# ESP32-C6 register map
Vendor: ESPRESSIF SYSTEMS (SHANGHAI) CO., LTD.; Series: ESP32 C-Series; File version: 12
CPU: RV32IMAC r0p0, little endian, no MPU, no FPU, 0 interrupt priority bits
Address unit: 32 bits
Registers are 32-bit, read-write, reset 0x0 unless marked. A register's access mark holds for its fields unless they carry their own. Offsets are from the block's base; [hi:lo] are bit positions; {n}, {i} and the like mark numbered series.

## SPI1 — SPI (Serial Peripheral Interface) Controller 1
Base 0x60003000
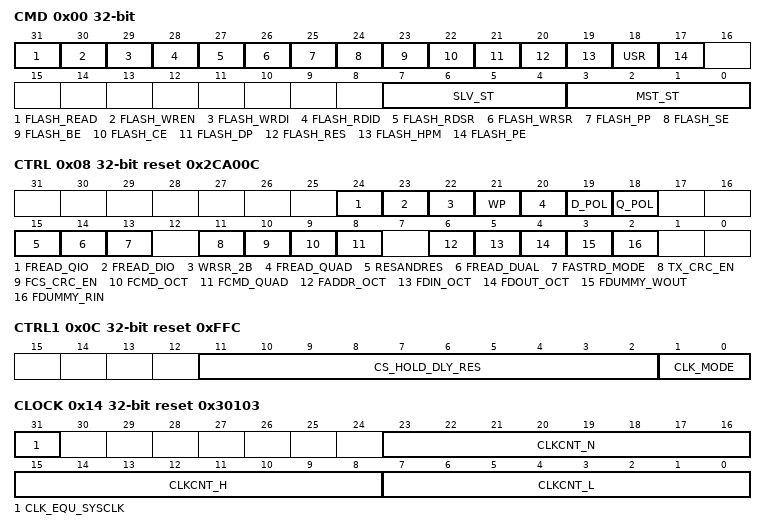
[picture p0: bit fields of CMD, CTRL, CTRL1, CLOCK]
0x00 CMD access per field — SPI1 memory command register
  [31] FLASH_READ rw — Read flash enable. Read flash operation will be triggered when the bit is set. The bit will be cleared once the operation done. 1: enable 0: disable.
  [30] FLASH_WREN rw — Write flash enable. Write enable command will be sent when the bit is set. The bit will be cleared once the operation done. 1: enable 0: disable.
  [29] FLASH_WRDI rw — Write flash disable. Write disable command will be sent when the bit is set. The bit will be cleared once the operation done. 1: enable 0: disable.
  [28] FLASH_RDID rw — Read JEDEC ID . Read ID command will be sent when the bit is set. The bit will be cleared once the operation done. 1: enable 0: disable.
  [27] FLASH_RDSR rw — Read status register-1. Read status operation will be triggered when the bit is set. The bit will be cleared once the operation done.1: enable 0: disable.
  [26] FLASH_WRSR rw — Write status register enable. Write status operation will be triggered when the bit is set. The bit will be cleared once the operation done.1: enable 0: disable.
  [25] FLASH_PP rw — Page program enable(1 byte ~256 bytes data to be programmed). Page program operation will be triggered when the bit is set. The bit will be cleared once the operation done .1: enable 0: disable.
  [24] FLASH_SE rw — Sector erase enable(4KB). Sector erase operation will be triggered when the bit is set. The bit will be cleared once the operation done.1: enable 0: disable.
  [23] FLASH_BE rw — Block erase enable(32KB) . Block erase operation will be triggered when the bit is set. The bit will be cleared once the operation done.1: enable 0: disable.
  [22] FLASH_CE rw — Chip erase enable. Chip erase operation will be triggered when the bit is set. The bit will be cleared once the operation done.1: enable 0: disable.
  [21] FLASH_DP rw — Drive Flash into power down. An operation will be triggered when the bit is set. The bit will be cleared once the operation done.1: enable 0: disable.
  [20] FLASH_RES rw — This bit combined with reg_resandres bit releases Flash from the power-down state or high performance mode and obtains the devices ID. The bit will be cleared once the operation done.1: enable 0: disable.
  [19] FLASH_HPM rw — Drive Flash into high performance mode. The bit will be cleared once the operation done.1: enable 0: disable.
  [18] USR rw — User define command enable. An operation will be triggered when the bit is set. The bit will be cleared once the operation done.1: enable 0: disable.
  [17] FLASH_PE rw — In user mode, it is set to indicate that program/erase operation will be triggered. The bit is combined with spi_mem_usr bit. The bit will be cleared once the operation done.1: enable 0: disable.
  [7:4] SLV_ST ro — The current status of SPI1 slave FSM: mspi_st. 0: idle state, 1: preparation state, 2: send command state, 3: send address state, 4: wait state, 5: read data state, 6:write data state, 7: done state, 8: read data end state.
  [3:0] MST_ST ro — The current status of SPI1 master FSM.
0x04 ADDR — SPI1 address register
  [31:0] USR_ADDR_VALUE — In user mode, it is the memory address. other then the bit0-bit23 is the memory address, the bit24-bit31 are the byte length of a transfer.
0x08 CTRL access per field reset 0x2CA00C — SPI1 control register.
  [24] FREAD_QIO rw — In the read operations address phase and read-data phase apply 4 signals. 1: enable 0: disable.
  [23] FREAD_DIO rw — In the read operations address phase and read-data phase apply 2 signals. 1: enable 0: disable.
  [22] WRSR_2B rw — two bytes data will be written to status register when it is set. 1: enable 0: disable.
  [21] WP rw — Write protect signal output when SPI is idle. 1: output high, 0: output low.
  [20] FREAD_QUAD rw — In the read operations read-data phase apply 4 signals. 1: enable 0: disable.
  [19] D_POL rw — The bit is used to set MOSI line polarity, 1: high 0, low
  [18] Q_POL rw — The bit is used to set MISO line polarity, 1: high 0, low
  [15] RESANDRES rw — The Device ID is read out to SPI_MEM_RD_STATUS register, this bit combine with spi_mem_flash_res bit. 1: enable 0: disable.
  [14] FREAD_DUAL rw — In the read operations, read-data phase apply 2 signals. 1: enable 0: disable.
  [13] FASTRD_MODE rw — This bit enable the bits: spi_mem_fread_qio, spi_mem_fread_dio, spi_mem_fread_qout and spi_mem_fread_dout. 1: enable 0: disable.
  [11] TX_CRC_EN ro — For SPI1, enable crc32 when writing encrypted data to flash. 1: enable 0:disable
  [10] FCS_CRC_EN ro — For SPI1, initialize crc32 module before writing encrypted data to flash. Active low.
  [9] FCMD_OCT ro — Apply 8 signals during command phase 1:enable 0: disable
  [8] FCMD_QUAD rw — Apply 4 signals during command phase 1:enable 0: disable
  [6] FADDR_OCT ro — Apply 8 signals during address phase 1:enable 0: disable
  [5] FDIN_OCT ro — Apply 8 signals during read-data phase 1:enable 0: disable
  [4] FDOUT_OCT ro — Apply 8 signals during write-data phase 1:enable 0: disable
  [3] FDUMMY_WOUT rw — In the dummy phase of a MSPI write data transfer when accesses to flash, the signal level of SPI bus is output by the MSPI controller.
  [2] FDUMMY_RIN rw — In the dummy phase of a MSPI read data transfer when accesses to flash, the signal level of SPI bus is output by the MSPI controller.
0x0C CTRL1 reset 0xFFC — SPI1 control1 register.
  [11:2] CS_HOLD_DLY_RES — After RES/DP/HPM command is sent, SPI1 waits (SPI_MEM_CS_HOLD_DELAY_RES[9:0] * 512) SPI_CLK cycles.
  [1:0] CLK_MODE — SPI clock mode bits. 0: SPI clock is off when CS inactive 1: SPI clock is delayed one cycle after CS inactive 2: SPI clock is delayed two cycles after CS inactive 3: SPI clock is alwasy on.
0x10 CTRL2 wo — SPI1 control2 register.
  [31] SYNC_RESET — The FSM will be reset.
0x14 CLOCK reset 0x30103 — SPI1 clock division control register.
  [31] CLK_EQU_SYSCLK — reserved
  [23:16] CLKCNT_N — In the master mode it is the divider of spi_mem_clk. So spi_mem_clk frequency is system/(spi_mem_clkcnt_N+1)
  [15:8] CLKCNT_H — In the master mode it must be floor((spi_mem_clkcnt_N+1)/2-1).
  [7:0] CLKCNT_L — In the master mode it must be equal to spi_mem_clkcnt_N.
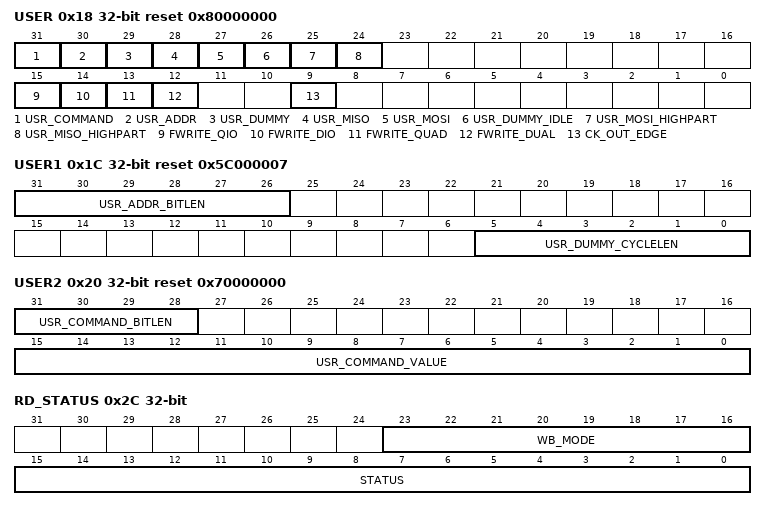
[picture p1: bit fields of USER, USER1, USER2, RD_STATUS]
0x18 USER access per field reset 0x80000000 — SPI1 user register.
  [31] USR_COMMAND rw — This bit enable the command phase of an operation.
  [30] USR_ADDR rw — This bit enable the address phase of an operation.
  [29] USR_DUMMY rw — This bit enable the dummy phase of an operation.
  [28] USR_MISO rw — This bit enable the read-data phase of an operation.
  [27] USR_MOSI rw — This bit enable the write-data phase of an operation.
  [26] USR_DUMMY_IDLE rw — SPI clock is disable in dummy phase when the bit is enable.
  [25] USR_MOSI_HIGHPART ro — write-data phase only access to high-part of the buffer spi_mem_w8~spi_mem_w15. 1: enable 0: disable.
  [24] USR_MISO_HIGHPART ro — read-data phase only access to high-part of the buffer spi_mem_w8~spi_mem_w15. 1: enable 0: disable.
  [15] FWRITE_QIO rw — In the write operations address phase and read-data phase apply 4 signals.
  [14] FWRITE_DIO rw — In the write operations address phase and read-data phase apply 2 signals.
  [13] FWRITE_QUAD rw — In the write operations read-data phase apply 4 signals
  [12] FWRITE_DUAL rw — In the write operations read-data phase apply 2 signals
  [9] CK_OUT_EDGE rw — the bit combined with spi_mem_mosi_delay_mode bits to set mosi signal delay mode.
0x1C USER1 reset 0x5C000007 — SPI1 user1 register.
  [31:26] USR_ADDR_BITLEN — The length in bits of address phase. The register value shall be (bit_num-1).
  [5:0] USR_DUMMY_CYCLELEN — The length in spi_mem_clk cycles of dummy phase. The register value shall be (cycle_num-1).
0x20 USER2 reset 0x70000000 — SPI1 user2 register.
  [31:28] USR_COMMAND_BITLEN — The length in bits of command phase. The register value shall be (bit_num-1)
  [15:0] USR_COMMAND_VALUE — The value of command.
0x24 MOSI_DLEN — SPI1 send data bit length control register.
  [9:0] USR_MOSI_DBITLEN — The length in bits of write-data. The register value shall be (bit_num-1).
0x28 MISO_DLEN — SPI1 receive data bit length control register.
  [9:0] USR_MISO_DBITLEN — The length in bits of read-data. The register value shall be (bit_num-1).
0x2C RD_STATUS — SPI1 status register.
  [23:16] WB_MODE — Mode bits in the flash fast read mode it is combined with spi_mem_fastrd_mode bit.
  [15:0] STATUS — The value is stored when set spi_mem_flash_rdsr bit and spi_mem_flash_res bit.
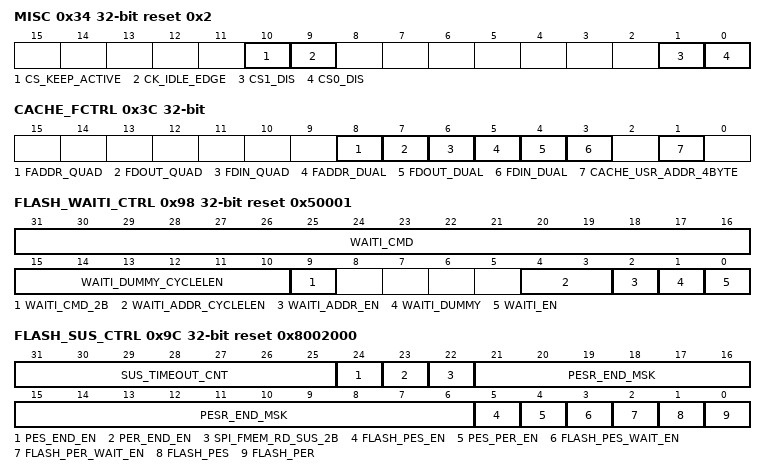
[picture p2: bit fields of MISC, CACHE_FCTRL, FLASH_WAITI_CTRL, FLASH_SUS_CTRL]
0x34 MISC reset 0x2 — SPI1 misc register
  [10] CS_KEEP_ACTIVE — spi cs line keep low when the bit is set.
  [9] CK_IDLE_EDGE — 1: spi clk line is high when idle 0: spi clk line is low when idle
  [1] CS1_DIS — SPI_CS1 pin enable, 1: disable SPI_CS1, 0: SPI_CS1 pin is active to select SPI device, such as flash, external RAM and so on.
  [0] CS0_DIS — SPI_CS0 pin enable, 1: disable SPI_CS0, 0: SPI_CS0 pin is active to select SPI device, such as flash, external RAM and so on.
0x38 TX_CRC ro reset 0xFFFFFFFF — SPI1 TX CRC data register.
  [31:0] DATA — For SPI1, the value of crc32.
0x3C CACHE_FCTRL — SPI1 bit mode control register.
  [8] FADDR_QUAD — For SPI1, address phase apply 4 signals. 1: enable 0: disable. The bit is the same with spi_mem_fread_qio.
  [7] FDOUT_QUAD — For SPI1, dout phase apply 4 signals. 1: enable 0: disable. The bit is the same with spi_mem_fread_qio.
  [6] FDIN_QUAD — For SPI1, din phase apply 4 signals. 1: enable 0: disable. The bit is the same with spi_mem_fread_qio.
  [5] FADDR_DUAL — For SPI1, address phase apply 2 signals. 1: enable 0: disable. The bit is the same with spi_mem_fread_dio.
  [4] FDOUT_DUAL — For SPI1, dout phase apply 2 signals. 1: enable 0: disable. The bit is the same with spi_mem_fread_dio.
  [3] FDIN_DUAL — For SPI1, din phase apply 2 signals. 1: enable 0: disable. The bit is the same with spi_mem_fread_dio.
  [1] CACHE_USR_ADDR_4BYTE — For SPI1, cache read flash with 4 bytes address, 1: enable, 0:disable.
{0x58+4i} W{i} (i=0..15) — SPI1 memory data buffer{i}
  [31:0] BUF — data buffer
0x98 FLASH_WAITI_CTRL reset 0x50001 — SPI1 wait idle control register
  [31:16] WAITI_CMD — The command value to wait flash idle(RDSR).
  [15:10] WAITI_DUMMY_CYCLELEN — The dummy cycle length when wait flash idle(RDSR).
  [9] WAITI_CMD_2B — 1:The wait idle command bit length is 16. 0: The wait idle command bit length is 8.
  [4:3] WAITI_ADDR_CYCLELEN — When SPI_MEM_WAITI_ADDR_EN is set, the cycle length of sent out address is (SPI_MEM_WAITI_ADDR_CYCLELEN[1:0] + 1) SPI bus clock cycles. It is not active when SPI_MEM_WAITI_ADDR_EN is cleared.
  [2] WAITI_ADDR_EN — 1: Output address 0 in RDSR or read SUS command transfer. 0: Do not send out address in RDSR or read SUS command transfer.
  [1] WAITI_DUMMY — The dummy phase enable when wait flash idle (RDSR)
  [0] WAITI_EN — 1: The hardware will wait idle after SE/PP/WRSR automatically, and hardware auto Suspend/Resume can be enabled. 0: The functions of hardware wait idle and auto Suspend/Resume are not supported.
0x9C FLASH_SUS_CTRL reset 0x8002000 — SPI1 flash suspend control register
  [31:25] SUS_TIMEOUT_CNT — When SPI1 checks SUS/SUS1/SUS2 bits fail for SPI_MEM_SUS_TIMEOUT_CNT[6:0] times, it will be treated as check pass.
  [24] PES_END_EN — 1: Both WIP and SUS/SUS1/SUS2 bits should be checked to insure the suspend status of flash. 0: Only need to check WIP is 0.
  [23] PER_END_EN — 1: Both WIP and SUS/SUS1/SUS2 bits should be checked to insure the resume status of flash. 0: Only need to check WIP is 0.
  [22] SPI_FMEM_RD_SUS_2B — 1: Read two bytes when check flash SUS/SUS1/SUS2 status bit. 0: Read one byte when check flash SUS/SUS1/SUS2 status bit
  [21:6] PESR_END_MSK — The mask value when check SUS/SUS1/SUS2 status bit. If the read status value is status_in[15:0](only status_in[7:0] is valid when only one byte of data is read out, status_in[15:0] is valid when two bytes of data are read out), SUS/SUS1/SUS2 = status_in[15:0]^ SPI_MEM_PESR_END_MSK[15:0].
  [5] FLASH_PES_EN — Set this bit to enable Auto-suspending function.
  [4] PES_PER_EN — Set this bit to enable PES end triggers PER transfer option. If this bit is 0, application should send PER after PES is done.
  [3] FLASH_PES_WAIT_EN — 1: SPI1 waits (SPI_MEM_CS_HOLD_DELAY_RES[9:0] * 4 or *128) SPI_CLK cycles after program erase suspend command is sent. 0: SPI1 does not wait after program erase suspend command is sent.
  [2] FLASH_PER_WAIT_EN — 1: SPI1 waits (SPI_MEM_CS_HOLD_DELAY_RES[9:0] * 4 or *128) SPI_CLK cycles after program erase resume command is sent. 0: SPI1 does not wait after program erase resume command is sent.
  [1] FLASH_PES — program erase suspend bit, program erase suspend operation will be triggered when the bit is set. The bit will be cleared once the operation done.1: enable 0: disable.
  [0] FLASH_PER — program erase resume bit, program erase suspend operation will be triggered when the bit is set. The bit will be cleared once the operation done.1: enable 0: disable.
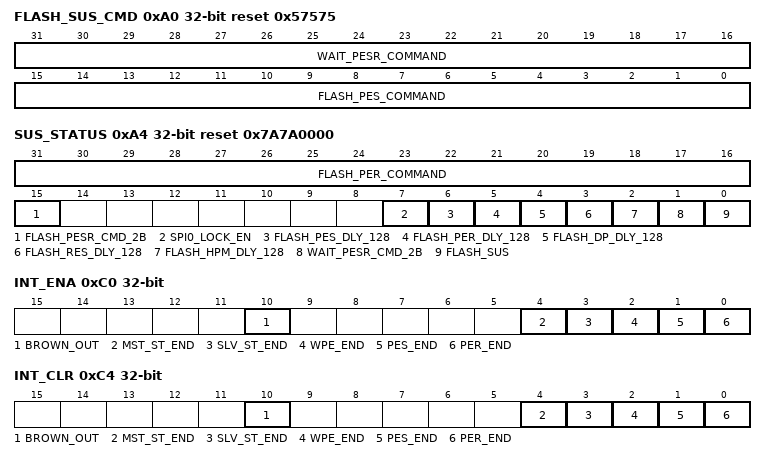
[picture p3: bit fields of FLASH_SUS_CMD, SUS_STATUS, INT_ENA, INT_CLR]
0xA0 FLASH_SUS_CMD reset 0x57575 — SPI1 flash suspend command register
  [31:16] WAIT_PESR_COMMAND — Flash SUS/SUS1/SUS2 status bit read command. The command should be sent when SUS/SUS1/SUS2 bit should be checked to insure the suspend or resume status of flash.
  [15:0] FLASH_PES_COMMAND — Program/Erase suspend command.
0xA4 SUS_STATUS reset 0x7A7A0000 — SPI1 flash suspend status register
  [31:16] FLASH_PER_COMMAND — Program/Erase resume command.
  [15] FLASH_PESR_CMD_2B — 1: The bit length of Program/Erase Suspend/Resume command is 16. 0: The bit length of Program/Erase Suspend/Resume command is 8.
  [7] SPI0_LOCK_EN — 1: Enable SPI0 lock SPI0/1 arbiter option. 0: Disable it.
  [6] FLASH_PES_DLY_128 — Valid when SPI_MEM_FLASH_PES_WAIT_EN is 1. 1: SPI1 waits (SPI_MEM_CS_HOLD_DELAY_RES[9:0] * 128) SPI_CLK cycles after PES command is sent. 0: SPI1 waits (SPI_MEM_CS_HOLD_DELAY_RES[9:0] * 4) SPI_CLK cycles after PES command is sent.
  [5] FLASH_PER_DLY_128 — Valid when SPI_MEM_FLASH_PER_WAIT_EN is 1. 1: SPI1 waits (SPI_MEM_CS_HOLD_DELAY_RES[9:0] * 128) SPI_CLK cycles after PER command is sent. 0: SPI1 waits (SPI_MEM_CS_HOLD_DELAY_RES[9:0] * 4) SPI_CLK cycles after PER command is sent.
  [4] FLASH_DP_DLY_128 — 1: SPI1 waits (SPI_MEM_CS_HOLD_DELAY_RES[9:0] * 128) SPI_CLK cycles after DP command is sent. 0: SPI1 waits (SPI_MEM_CS_HOLD_DELAY_RES[9:0] * 4) SPI_CLK cycles after DP command is sent.
  [3] FLASH_RES_DLY_128 — 1: SPI1 waits (SPI_MEM_CS_HOLD_DELAY_RES[9:0] * 128) SPI_CLK cycles after RES command is sent. 0: SPI1 waits (SPI_MEM_CS_HOLD_DELAY_RES[9:0] * 4) SPI_CLK cycles after RES command is sent.
  [2] FLASH_HPM_DLY_128 — 1: SPI1 waits (SPI_MEM_CS_HOLD_DELAY_RES[9:0] * 128) SPI_CLK cycles after HPM command is sent. 0: SPI1 waits (SPI_MEM_CS_HOLD_DELAY_RES[9:0] * 4) SPI_CLK cycles after HPM command is sent.
  [1] WAIT_PESR_CMD_2B — 1: SPI1 sends out SPI_MEM_WAIT_PESR_COMMAND[15:0] to check SUS/SUS1/SUS2 bit. 0: SPI1 sends out SPI_MEM_WAIT_PESR_COMMAND[7:0] to check SUS/SUS1/SUS2 bit.
  [0] FLASH_SUS — The status of flash suspend, only used in SPI1.
0xC0 INT_ENA — SPI1 interrupt enable register
  [10] BROWN_OUT — The enable bit for SPI_MEM_BROWN_OUT_INT interrupt.
  [4] MST_ST_END — The enable bit for SPI_MEM_MST_ST_END_INT interrupt.
  [3] SLV_ST_END — The enable bit for SPI_MEM_SLV_ST_END_INT interrupt.
  [2] WPE_END — The enable bit for SPI_MEM_WPE_END_INT interrupt.
  [1] PES_END — The enable bit for SPI_MEM_PES_END_INT interrupt.
  [0] PER_END — The enable bit for SPI_MEM_PER_END_INT interrupt.
0xC4 INT_CLR wo — SPI1 interrupt clear register
  [10] BROWN_OUT write-1-clears — The status bit for SPI_MEM_BROWN_OUT_INT interrupt.
  [4] MST_ST_END write-1-clears — The clear bit for SPI_MEM_MST_ST_END_INT interrupt.
  [3] SLV_ST_END write-1-clears — The clear bit for SPI_MEM_SLV_ST_END_INT interrupt.
  [2] WPE_END write-1-clears — The clear bit for SPI_MEM_WPE_END_INT interrupt.
  [1] PES_END write-1-clears — The clear bit for SPI_MEM_PES_END_INT interrupt.
  [0] PER_END write-1-clears — The clear bit for SPI_MEM_PER_END_INT interrupt.
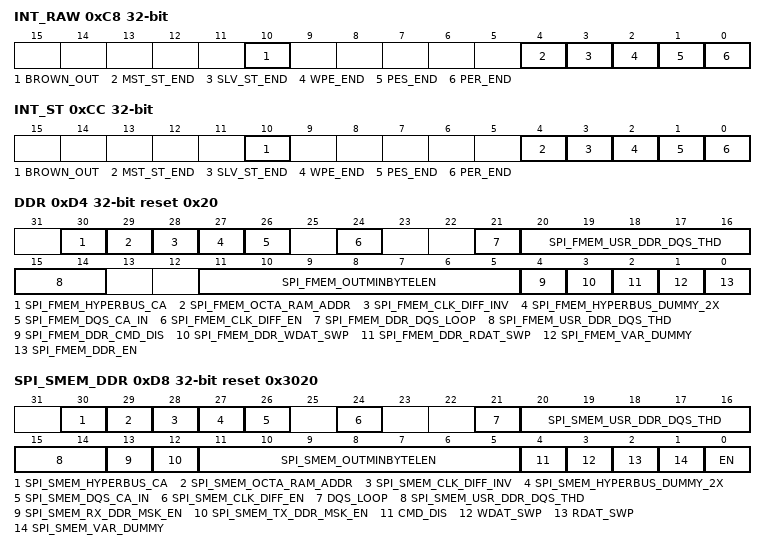
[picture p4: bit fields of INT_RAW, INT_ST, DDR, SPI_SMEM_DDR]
0xC8 INT_RAW — SPI1 interrupt raw register
  [10] BROWN_OUT — The raw bit for SPI_MEM_BROWN_OUT_INT interrupt. 1: Triggered condition is that chip is loosing power and RTC module sends out brown out close flash request to SPI1. After SPI1 sends out suspend command to flash, this interrupt is triggered and MSPI returns to idle state. 0: Others.
  [4] MST_ST_END — The raw bit for SPI_MEM_MST_ST_END_INT interrupt. 1: Triggered when spi1_mst_st is changed from non idle state to idle state. 0: Others.
  [3] SLV_ST_END — The raw bit for SPI_MEM_SLV_ST_END_INT interrupt. 1: Triggered when spi1_slv_st is changed from non idle state to idle state. It means that SPI_CS raises high. 0: Others
  [2] WPE_END — The raw bit for SPI_MEM_WPE_END_INT interrupt. 1: Triggered when WRSR/PP/SE/BE/CE is sent and flash is already idle. 0: Others.
  [1] PES_END — The raw bit for SPI_MEM_PES_END_INT interrupt.1: Triggered when Auto Suspend command (0x75) is sent and flash is suspended successfully. 0: Others.
  [0] PER_END — The raw bit for SPI_MEM_PER_END_INT interrupt. 1: Triggered when Auto Resume command (0x7A) is sent and flash is resumed successfully. 0: Others.
0xCC INT_ST ro — SPI1 interrupt status register
  [10] BROWN_OUT — The status bit for SPI_MEM_BROWN_OUT_INT interrupt.
  [4] MST_ST_END — The status bit for SPI_MEM_MST_ST_END_INT interrupt.
  [3] SLV_ST_END — The status bit for SPI_MEM_SLV_ST_END_INT interrupt.
  [2] WPE_END — The status bit for SPI_MEM_WPE_END_INT interrupt.
  [1] PES_END — The status bit for SPI_MEM_PES_END_INT interrupt.
  [0] PER_END — The status bit for SPI_MEM_PER_END_INT interrupt.
0xD4 DDR ro reset 0x20 — SPI1 DDR control register
  [30] SPI_FMEM_HYPERBUS_CA — Set this bit to enable HyperRAM address out when accesses to flash, which means ADDR_OUT[31:0] = {spi_usr_addr_value[19:4], 13'd0, spi_usr_addr_value[3:1]}.
  [29] SPI_FMEM_OCTA_RAM_ADDR — Set this bit to enable octa_ram address out when accesses to flash, which means ADDR_OUT[31:0] = {spi_usr_addr_value[25:4], 6'd0, spi_usr_addr_value[3:1], 1'b0}.
  [28] SPI_FMEM_CLK_DIFF_INV — Set this bit to invert SPI_DIFF when accesses to flash. .
  [27] SPI_FMEM_HYPERBUS_DUMMY_2X — Set this bit to enable the vary dummy function in SPI HyperBus mode, when SPI0 accesses flash or SPI1 accesses flash or sram.
  [26] SPI_FMEM_DQS_CA_IN — Set this bit to enable the input of SPI_DQS signal in SPI phases of CMD and ADDR.
  [24] SPI_FMEM_CLK_DIFF_EN — Set this bit to enable the differential SPI_CLK#.
  [21] SPI_FMEM_DDR_DQS_LOOP — 1: Do not need the input of SPI_DQS signal, SPI0 starts to receive data when spi0_slv_st is in SPI_MEM_DIN state. It is used when there is no SPI_DQS signal or SPI_DQS signal is not stable. 0: SPI0 starts to store data at the positive and negative edge of SPI_DQS.
  [20:14] SPI_FMEM_USR_DDR_DQS_THD — The delay number of data strobe which from memory based on SPI clock.
  [11:5] SPI_FMEM_OUTMINBYTELEN — It is the minimum output data length in the panda device.
  [4] SPI_FMEM_DDR_CMD_DIS — the bit is used to disable dual edge in command phase when ddr mode.
  [3] SPI_FMEM_DDR_WDAT_SWP — Set the bit to reorder tx data of the word in spi ddr mode.
  [2] SPI_FMEM_DDR_RDAT_SWP — Set the bit to reorder rx data of the word in spi ddr mode.
  [1] SPI_FMEM_VAR_DUMMY — Set the bit to enable variable dummy cycle in spi ddr mode.
  [0] SPI_FMEM_DDR_EN — 1: in ddr mode, 0 in sdr mode
0xD8 SPI_SMEM_DDR ro reset 0x3020 — MSPI external RAM DDR mode control register
  [30] SPI_SMEM_HYPERBUS_CA — Set this bit to enable HyperRAM address out when accesses to external RAM, which means ADDR_OUT[31:0] = {spi_usr_addr_value[19:4], 13'd0, spi_usr_addr_value[3:1]}.
  [29] SPI_SMEM_OCTA_RAM_ADDR — Set this bit to enable octa_ram address out when accesses to external RAM, which means ADDR_OUT[31:0] = {spi_usr_addr_value[25:4], 6'd0, spi_usr_addr_value[3:1], 1'b0}.
  [28] SPI_SMEM_CLK_DIFF_INV — Set this bit to invert SPI_DIFF when accesses to external RAM. .
  [27] SPI_SMEM_HYPERBUS_DUMMY_2X — Set this bit to enable the vary dummy function in SPI HyperBus mode, when SPI0 accesses flash or SPI1 accesses flash or sram.
  [26] SPI_SMEM_DQS_CA_IN — Set this bit to enable the input of SPI_DQS signal in SPI phases of CMD and ADDR.
  [24] SPI_SMEM_CLK_DIFF_EN — Set this bit to enable the differential SPI_CLK#.
  [21] DQS_LOOP — 1: Do not need the input of SPI_DQS signal, SPI0 starts to receive data when spi0_slv_st is in SPI_MEM_DIN state. It is used when there is no SPI_DQS signal or SPI_DQS signal is not stable. 0: SPI0 starts to store data at the positive and negative edge of SPI_DQS.
  [20:14] SPI_SMEM_USR_DDR_DQS_THD — The delay number of data strobe which from memory based on SPI clock.
  [13] SPI_SMEM_RX_DDR_MSK_EN — Set this bit to mask the first or the last byte in SPI0 ECC DDR read mode, when accesses to external RAM.
  [12] SPI_SMEM_TX_DDR_MSK_EN — Set this bit to mask the first or the last byte in SPI0 ECC DDR write mode, when accesses to external RAM.
  [11:5] SPI_SMEM_OUTMINBYTELEN — It is the minimum output data length in the DDR psram.
  [4] CMD_DIS — the bit is used to disable dual edge in command phase when DDR mode.
  [3] WDAT_SWP — Set the bit to reorder tx data of the word in spi DDR mode.
  [2] RDAT_SWP — Set the bit to reorder rx data of the word in spi DDR mode.
  [1] SPI_SMEM_VAR_DUMMY — Set the bit to enable variable dummy cycle in spi DDR mode.
  [0] EN — 1: in DDR mode, 0 in SDR mode
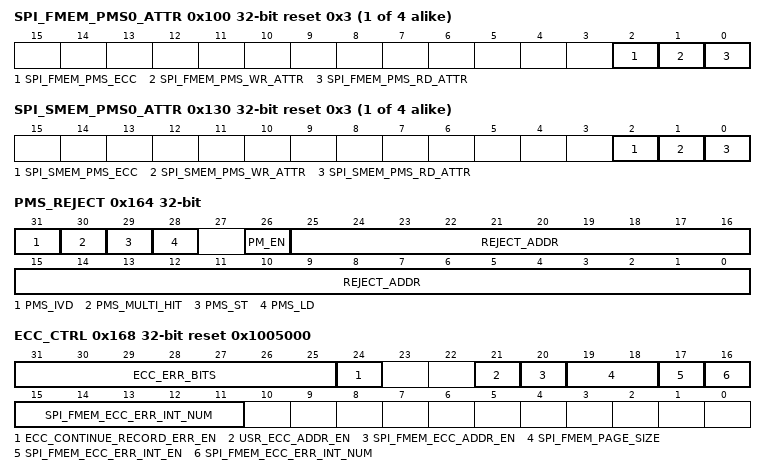
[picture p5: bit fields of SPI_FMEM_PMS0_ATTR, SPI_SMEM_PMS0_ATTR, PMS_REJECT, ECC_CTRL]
{0x100+4i} SPI_FMEM_PMS{i}_ATTR (i=0..3) reset 0x3 — MSPI flash ACE section {i} attribute register
  [2] SPI_FMEM_PMS_ECC — SPI1 flash ACE section %s ECC mode, 1: enable ECC mode. 0: Disable it. The flash ACE section %s is configured by registers SPI_FMEM_PMS%s_ADDR_REG and SPI_FMEM_PMS%s_SIZE_REG.
  [1] SPI_FMEM_PMS_WR_ATTR — 1: SPI1 flash ACE section %s write accessible. 0: Not allowed.
  [0] SPI_FMEM_PMS_RD_ATTR — 1: SPI1 flash ACE section %s read accessible. 0: Not allowed.
{0x110+4i} SPI_FMEM_PMS{i}_ADDR (i=0..3) — SPI1 flash ACE section {i} start address register
  [25:0] S — SPI1 flash ACE section %s start address value
{0x120+4i} SPI_FMEM_PMS{i}_SIZE (i=0..3) reset 0x1000 — SPI1 flash ACE section {i} start address register
  [13:0] SPI_FMEM_PMS_SIZE — SPI1 flash ACE section %s address region is (SPI_FMEM_PMS%s_ADDR_S, SPI_FMEM_PMS%s_ADDR_S + SPI_FMEM_PMS%s_SIZE)
{0x130+4i} SPI_SMEM_PMS{i}_ATTR (i=0..3) reset 0x3 — SPI1 flash ACE section {i} start address register
  [2] SPI_SMEM_PMS_ECC — SPI1 external RAM ACE section %s ECC mode, 1: enable ECC mode. 0: Disable it. The external RAM ACE section %s is configured by registers SPI_SMEM_PMS%s_ADDR_REG and SPI_SMEM_PMS%s_SIZE_REG.
  [1] SPI_SMEM_PMS_WR_ATTR — 1: SPI1 external RAM ACE section %s write accessible. 0: Not allowed.
  [0] SPI_SMEM_PMS_RD_ATTR — 1: SPI1 external RAM ACE section %s read accessible. 0: Not allowed.
{0x140+4i} SPI_SMEM_PMS{i}_ADDR (i=0..3) — SPI1 external RAM ACE section {i} start address register
  [25:0] S — SPI1 external RAM ACE section %s start address value
{0x150+4i} SPI_SMEM_PMS{i}_SIZE (i=0..3) reset 0x1000 — SPI1 external RAM ACE section {i} start address register
  [13:0] SPI_SMEM_PMS_SIZE — SPI1 external RAM ACE section %s address region is (SPI_SMEM_PMS%s_ADDR_S, SPI_SMEM_PMS%s_ADDR_S + SPI_SMEM_PMS%s_SIZE)
0x164 PMS_REJECT access per field — SPI1 access reject register
  [31] PMS_IVD ro — 1: SPI1 access is rejected because of address multi-hit. 0: No address multi-hit error. It is cleared by when SPI_MEM_PMS_REJECT_INT_CLR bit is set.
  [30] PMS_MULTI_HIT ro — 1: SPI1 access is rejected because of address miss. 0: No address miss error. It is cleared by when SPI_MEM_PMS_REJECT_INT_CLR bit is set.
  [29] PMS_ST ro — 1: SPI1 read access error. 0: No read access error. It is cleared by when SPI_MEM_PMS_REJECT_INT_CLR bit is set.
  [28] PMS_LD ro — 1: SPI1 write access error. 0: No write access error. It is cleared by when SPI_MEM_PMS_REJECT_INT_CLR bit is set.
  [26] PM_EN rw — Set this bit to enable SPI0/1 transfer permission control function.
  [25:0] REJECT_ADDR ro — This bits show the first SPI1 access error address. It is cleared by when SPI_MEM_PMS_REJECT_INT_CLR bit is set.
0x168 ECC_CTRL access per field reset 0x1005000 — MSPI ECC control register
  [31:25] ECC_ERR_BITS ro — Records the first ECC error bit number in the 16 bytes(From 0~127, corresponding to byte 0 bit 0 to byte 15 bit 7)
  [24] ECC_CONTINUE_RECORD_ERR_EN ro — 1: The error information in SPI_MEM_ECC_ERR_BITS and SPI_MEM_ECC_ERR_ADDR is updated when there is an ECC error. 0: SPI_MEM_ECC_ERR_BITS and SPI_MEM_ECC_ERR_ADDR record the first ECC error information.
  [21] USR_ECC_ADDR_EN ro — Set this bit to enable ECC address convert in SPI0/1 USR_CMD transfer.
  [20] SPI_FMEM_ECC_ADDR_EN ro — Set this bit to enable MSPI ECC address conversion, no matter MSPI accesses to the ECC region or non-ECC region of flash. If there is no ECC region in flash, this bit should be 0. Otherwise, this bit should be 1.
  [19:18] SPI_FMEM_PAGE_SIZE rw — Set the page size of the flash accessed by MSPI. 0: 256 bytes. 1: 512 bytes. 2: 1024 bytes. 3: 2048 bytes.
  [17] SPI_FMEM_ECC_ERR_INT_EN ro — Set this bit to calculate the error times of MSPI ECC read when accesses to flash.
  [16:11] SPI_FMEM_ECC_ERR_INT_NUM ro — Set the error times of MSPI ECC read to generate MSPI SPI_MEM_ECC_ERR_INT interrupt.
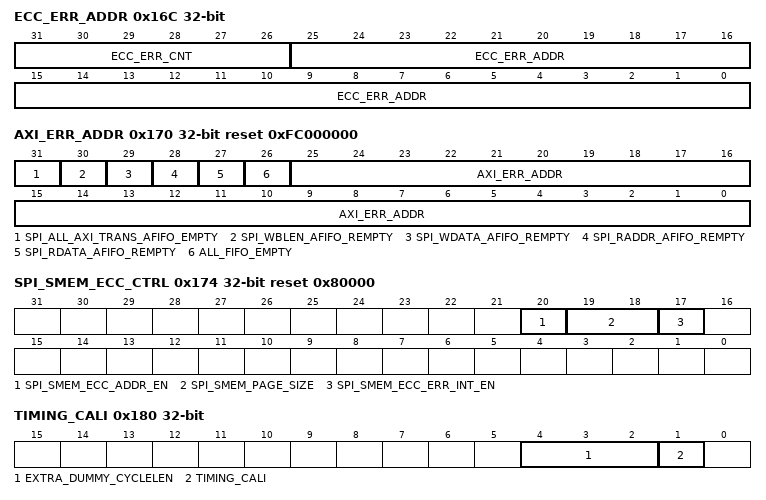
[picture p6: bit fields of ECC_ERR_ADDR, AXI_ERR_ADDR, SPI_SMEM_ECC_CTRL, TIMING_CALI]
0x16C ECC_ERR_ADDR ro — MSPI ECC error address register
  [31:26] ECC_ERR_CNT — This bits show the error times of MSPI ECC read. It is cleared by when SPI_MEM_ECC_ERR_INT_CLR bit is set.
  [25:0] ECC_ERR_ADDR — This bits show the first MSPI ECC error address. It is cleared by when SPI_MEM_ECC_ERR_INT_CLR bit is set.
0x170 AXI_ERR_ADDR ro reset 0xFC000000 — MSPI AXI request error address
  [31] SPI_ALL_AXI_TRANS_AFIFO_EMPTY — This bit is set when WADDR_AFIFO, WBLEN_AFIFO, WDATA_AFIFO, AXI_RADDR_CTL_AFIFO and RDATA_AFIFO are empty and spi0_mst_st is IDLE.
  [30] SPI_WBLEN_AFIFO_REMPTY — 1: WBLEN_AFIFO is empty. 0: At least one AXI write transfer is pending.
  [29] SPI_WDATA_AFIFO_REMPTY — 1: WDATA_AFIFO is empty. 0: At least one AXI write transfer is pending.
  [28] SPI_RADDR_AFIFO_REMPTY — 1: AXI_RADDR_CTL_AFIFO is empty. 0: At least one AXI read transfer is pending.
  [27] SPI_RDATA_AFIFO_REMPTY — 1: RDATA_AFIFO is empty. 0: At least one AXI read transfer is pending.
  [26] ALL_FIFO_EMPTY — The empty status of all AFIFO and SYNC_FIFO in MSPI module. 1: All AXI transfers and SPI0 transfers are done. 0: Others.
  [25:0] AXI_ERR_ADDR — This bits show the first AXI write/read invalid error or AXI write flash error address. It is cleared by when SPI_MEM_AXI_WADDR_ERR_INT_CLR, SPI_MEM_AXI_WR_FLASH_ERR_IN_CLR or SPI_MEM_AXI_RADDR_ERR_IN_CLR bit is set.
0x174 SPI_SMEM_ECC_CTRL ro reset 0x80000 — MSPI ECC control register
  [20] SPI_SMEM_ECC_ADDR_EN — Set this bit to enable MSPI ECC address conversion, no matter MSPI accesses to the ECC region or non-ECC region of external RAM. If there is no ECC region in external RAM, this bit should be 0. Otherwise, this bit should be 1.
  [19:18] SPI_SMEM_PAGE_SIZE — Set the page size of the external RAM accessed by MSPI. 0: 256 bytes. 1: 512 bytes. 2: 1024 bytes. 3: 2048 bytes.
  [17] SPI_SMEM_ECC_ERR_INT_EN — Set this bit to calculate the error times of MSPI ECC read when accesses to external RAM.
0x180 TIMING_CALI — SPI1 timing control register
  [4:2] EXTRA_DUMMY_CYCLELEN — add extra dummy spi clock cycle length for spi clock calibration.
  [1] TIMING_CALI — The bit is used to enable timing auto-calibration for all reading operations.
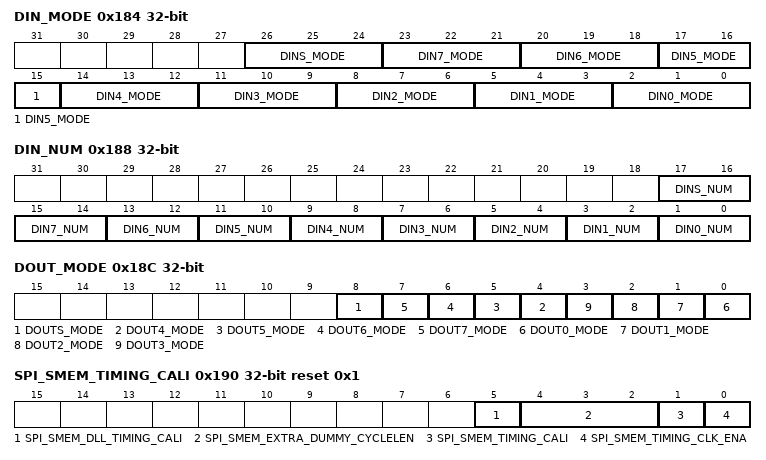
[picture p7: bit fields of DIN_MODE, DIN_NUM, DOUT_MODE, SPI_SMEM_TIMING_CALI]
0x184 DIN_MODE — MSPI flash input timing delay mode control register
  [26:24] DINS_MODE — the input signals are delayed by system clock cycles, 0: input without delayed, 1: input with the posedge of clk_apb,2 input with the negedge of clk_apb, 3: input with the spi_clk
  [3n+2:3n] DIN{n}_MODE (n=4..7) — the input signals are delayed by system clock cycles, 0: input without delayed, 1: input with the posedge of clk_apb,2 input with the negedge of clk_apb, 3: input with the spi_clk
  [3n+2:3n] DIN{n}_MODE (n=0..3) — the input signals are delayed by system clock cycles, 0: input without delayed, 1: input with the posedge of clk_apb,2 input with the negedge of clk_apb, 3: input with the posedge of clk_160, 4 input with the negedge of clk_160, 5: input with the spi_clk high edge, 6: input with the spi_clk low edge
0x188 DIN_NUM — MSPI flash input timing delay number control register
  [17:16] DINS_NUM — the input signals are delayed by system clock cycles, 0: delayed by 1 cycle, 1: delayed by 2 cycles,...
  [2n+1:2n] DIN{n}_NUM (n=0..7) — the input signals are delayed by system clock cycles, 0: delayed by 1 cycle, 1: delayed by 2 cycles,...
0x18C DOUT_MODE — MSPI flash output timing adjustment control register
  [8] DOUTS_MODE — the output signals are delayed by system clock cycles, 0: output without delayed, 1: output with the posedge of clk_apb,2 output with the negedge of clk_apb, 3: output with the spi_clk
  [n] DOUT{n}_MODE (n=4..7) — the output signals are delayed by system clock cycles, 0: output without delayed, 1: output with the posedge of clk_apb,2 output with the negedge of clk_apb, 3: output with the spi_clk
  [n] DOUT{n}_MODE (n=0..3) — the output signals are delayed by system clock cycles, 0: output without delayed, 1: output with the posedge of clk_apb,2 output with the negedge of clk_apb, 3: output with the posedge of clk_160,4 output with the negedge of clk_160,5: output with the spi_clk high edge ,6: output with the spi_clk low edge
0x190 SPI_SMEM_TIMING_CALI ro reset 0x1 — MSPI external RAM timing calibration register
  [5] SPI_SMEM_DLL_TIMING_CALI — Set this bit to enable DLL for timing calibration in DDR mode when accessed to EXT_RAM.
  [4:2] SPI_SMEM_EXTRA_DUMMY_CYCLELEN — For sram, add extra dummy spi clock cycle length for spi clock calibration.
  [1] SPI_SMEM_TIMING_CALI — For sram, the bit is used to enable timing auto-calibration for all reading operations.
  [0] SPI_SMEM_TIMING_CLK_ENA — For sram, the bit is used to enable timing adjust clock for all reading operations.
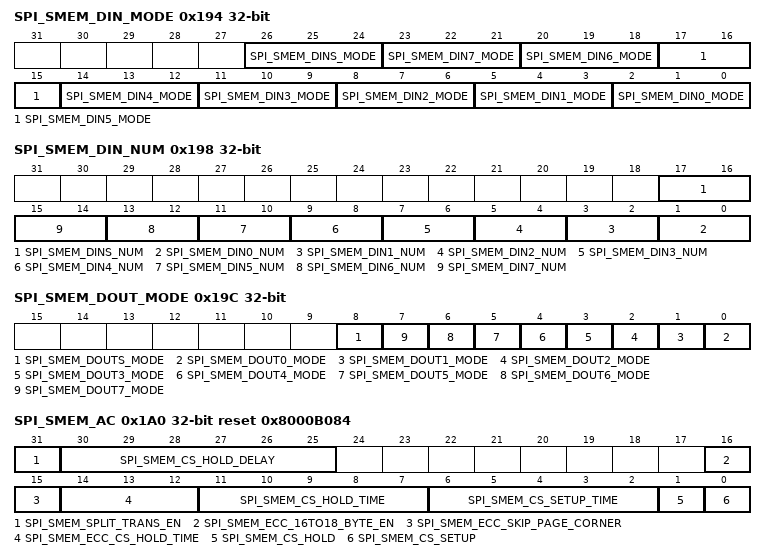
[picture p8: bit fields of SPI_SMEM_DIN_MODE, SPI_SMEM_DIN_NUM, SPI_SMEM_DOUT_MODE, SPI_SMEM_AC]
0x194 SPI_SMEM_DIN_MODE ro — MSPI external RAM input timing delay mode control register
  [26:24] SPI_SMEM_DINS_MODE — the input signals are delayed by system clock cycles, 0: input without delayed, 1: input with the posedge of clk_apb,2 input with the negedge of clk_apb, 3: input with the posedge of clk_160, 4 input with the negedge of clk_160, 5: input with the spi_clk high edge, 6: input with the spi_clk low edge
  [3n+2:3n] SPI_SMEM_DIN{n}_MODE (n=0..7) — the input signals are delayed by system clock cycles, 0: input without delayed, 1: input with the posedge of clk_apb,2 input with the negedge of clk_apb, 3: input with the posedge of clk_160, 4 input with the negedge of clk_160, 5: input with the spi_clk high edge, 6: input with the spi_clk low edge
0x198 SPI_SMEM_DIN_NUM ro — MSPI external RAM input timing delay number control register
  [17:16] SPI_SMEM_DINS_NUM — the input signals are delayed by system clock cycles, 0: input without delayed, 1: input with the posedge of clk_apb,2 input with the negedge of clk_apb, 3: input with the posedge of clk_160, 4 input with the negedge of clk_160, 5: input with the spi_clk high edge, 6: input with the spi_clk low edge
  [2n+1:2n] SPI_SMEM_DIN{n}_NUM (n=0..7) — the input signals are delayed by system clock cycles, 0: delayed by 1 cycle, 1: delayed by 2 cycles,...
0x19C SPI_SMEM_DOUT_MODE ro — MSPI external RAM output timing adjustment control register
  [8] SPI_SMEM_DOUTS_MODE — the output signals are delayed by system clock cycles, 0: output without delayed, 1: output with the posedge of clk_apb,2 output with the negedge of clk_apb, 3: output with the posedge of clk_160,4 output with the negedge of clk_160,5: output with the spi_clk high edge ,6: output with the spi_clk low edge
  [n] SPI_SMEM_DOUT{n}_MODE (n=0..7) — the output signals are delayed by system clock cycles, 0: output without delayed, 1: output with the posedge of clk_apb,2 output with the negedge of clk_apb, 3: output with the posedge of clk_160,4 output with the negedge of clk_160,5: output with the spi_clk high edge ,6: output with the spi_clk low edge
0x1A0 SPI_SMEM_AC ro reset 0x8000B084 — MSPI external RAM ECC and SPI CS timing control register
  [31] SPI_SMEM_SPLIT_TRANS_EN — Set this bit to enable SPI0 split one AXI accesses EXT_RAM transfer into two SPI transfers when one transfer will cross flash/EXT_RAM page corner, valid no matter whether there is an ECC region or not.
  [30:25] SPI_SMEM_CS_HOLD_DELAY — These bits are used to set the minimum CS high time tSHSL between SPI burst transfer when accesses to external RAM. tSHSL is (SPI_SMEM_CS_HOLD_DELAY[5:0] + 1) MSPI core clock cycles.
  [16] SPI_SMEM_ECC_16TO18_BYTE_EN — Set this bit to enable SPI0 and SPI1 ECC 16 bytes data with 2 ECC bytes mode when accesses external RAM.
  [15] SPI_SMEM_ECC_SKIP_PAGE_CORNER — 1: SPI0 skips page corner when accesses external RAM. 0: Not skip page corner when accesses external RAM.
  [14:12] SPI_SMEM_ECC_CS_HOLD_TIME — SPI_SMEM_CS_HOLD_TIME + SPI_SMEM_ECC_CS_HOLD_TIME is the SPI0 and SPI1 CS hold cycles in ECC mode when accessed external RAM.
  [11:7] SPI_SMEM_CS_HOLD_TIME — For SPI0 and SPI1, spi cs signal is delayed to inactive by spi clock this bits are combined with spi_mem_cs_hold bit.
  [6:2] SPI_SMEM_CS_SETUP_TIME — For spi0, (cycles-1) of prepare phase by spi clock this bits are combined with spi_mem_cs_setup bit.
  [1] SPI_SMEM_CS_HOLD — For SPI0 and SPI1, spi cs keep low when spi is in done phase. 1: enable 0: disable.
  [0] SPI_SMEM_CS_SETUP — For SPI0 and SPI1, spi cs is enable when spi is in prepare phase. 1: enable 0: disable.
0x200 CLOCK_GATE reset 0x1 — SPI1 clk_gate register
  [0] CLK_EN — Register clock gate enable signal. 1: Enable. 0: Disable.
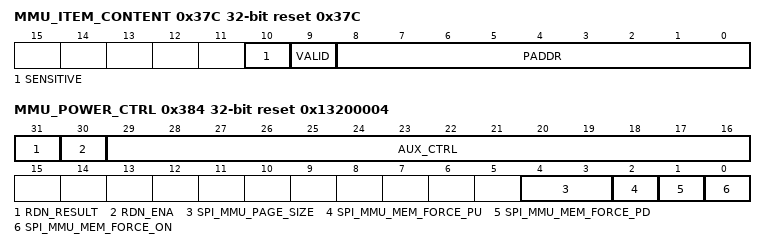
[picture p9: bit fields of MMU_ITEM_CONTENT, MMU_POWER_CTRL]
0x37C MMU_ITEM_CONTENT reset 0x37C — MSPI-MMU item content register
  [10] SENSITIVE — Decrypt via flash encryption when set
  [9] VALID — Entry is valid when set
  [8:0] PADDR — Physical page number
0x380 MMU_ITEM_INDEX — MSPI-MMU item index register
  [31:0] MMU_ITEM_INDEX — MSPI-MMU item index
0x384 MMU_POWER_CTRL access per field reset 0x13200004 — MSPI MMU power control register
  [31] RDN_RESULT ro — MSPI module clock domain and AXI clock domain ECO register result register
  [30] RDN_ENA ro — ECO register enable bit
  [29:16] AUX_CTRL ro — MMU PSRAM aux control register
  [4:3] SPI_MMU_PAGE_SIZE rw — 0: Max page size , 1: Max page size/2 , 2: Max page size/4, 3: Max page size/8
  [2] SPI_MMU_MEM_FORCE_PU rw — Set this bit to force mmu-memory powerup, in this case, the power should also be controlled by rtc.
  [1] SPI_MMU_MEM_FORCE_PD rw — Set this bit to force mmu-memory powerdown
  [0] SPI_MMU_MEM_FORCE_ON rw — Set this bit to enable mmu-memory clock force on
0x3F0 REGISTERRND_ECO_HIGH ro reset 0x37C — MSPI ECO high register
  [31:0] REGISTERRND_ECO_HIGH — ECO high register
0x3F4 REGISTERRND_ECO_LOW ro reset 0x37C — MSPI ECO low register
  [31:0] REGISTERRND_ECO_LOW — ECO low register
0x3FC DATE — Version control register
